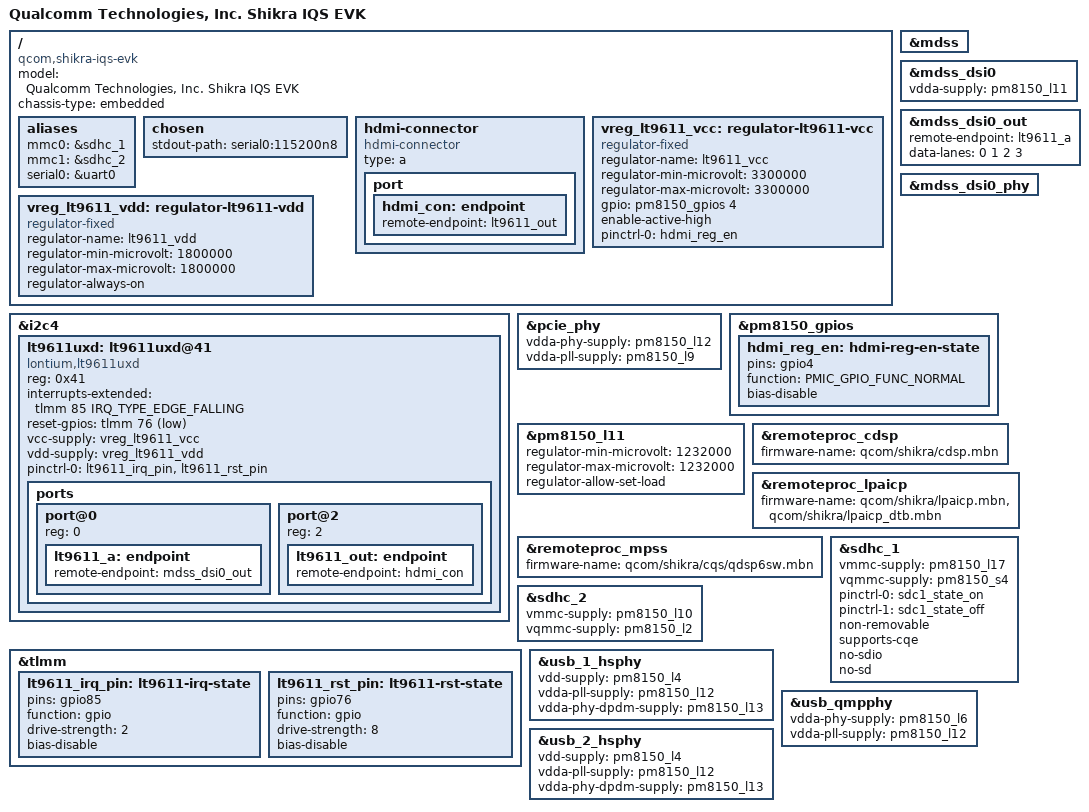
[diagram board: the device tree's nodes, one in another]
// SPDX-License-Identifier: BSD-3-Clause
/*
 * Copyright (c) Qualcomm Technologies, Inc. and/or its subsidiaries.
 */

/dts-v1/;

#include "shikra-iqs-som.dtsi"
#include "shikra-evk.dtsi"
#include <dt-bindings/gpio/gpio.h>
#include <dt-bindings/interrupt-controller/irq.h>

/ {
	model = "Qualcomm Technologies, Inc. Shikra IQS EVK";
	compatible = "qcom,shikra-iqs-evk", "qcom,shikra-iqs-som", "qcom,shikra";
	chassis-type = "embedded";

	aliases {
		mmc0 = &sdhc_1;
		mmc1 = &sdhc_2; /* SDC2 SD card slot */
		serial0 = &uart0;
	};

	chosen {
		stdout-path = "serial0:115200n8";
	};

	hdmi-connector {
		compatible = "hdmi-connector";
		type = "a";

		port {
			hdmi_con: endpoint {
				remote-endpoint = <&lt9611_out>;
			};
		};
	};

	vreg_lt9611_vcc: regulator-lt9611-vcc {
		compatible = "regulator-fixed";
		regulator-name = "lt9611_vcc";
		regulator-min-microvolt = <3300000>;
		regulator-max-microvolt = <3300000>;
		gpio = <&pm8150_gpios 4 GPIO_ACTIVE_HIGH>;
		enable-active-high;
		pinctrl-0 = <&hdmi_reg_en>;
		pinctrl-names = "default";
	};

	vreg_lt9611_vdd: regulator-lt9611-vdd {
		compatible = "regulator-fixed";
		regulator-name = "lt9611_vdd";
		regulator-min-microvolt = <1800000>;
		regulator-max-microvolt = <1800000>;
		regulator-always-on;
	};
};

&i2c4 {
	status = "okay";

	lt9611uxd: lt9611uxd@41 {
		compatible = "lontium,lt9611uxd";
		reg = <0x41>;
		interrupts-extended = <&tlmm 85 IRQ_TYPE_EDGE_FALLING>;
		reset-gpios = <&tlmm 76 GPIO_ACTIVE_LOW>;
		vcc-supply = <&vreg_lt9611_vcc>;
		vdd-supply = <&vreg_lt9611_vdd>;

		pinctrl-0 = <&lt9611_irq_pin &lt9611_rst_pin>;
		pinctrl-names = "default";

		ports {
			#address-cells = <1>;
			#size-cells = <0>;

			port@0 {
				reg = <0>;

				lt9611_a: endpoint {
					remote-endpoint = <&mdss_dsi0_out>;
				};
			};

			port@2 {
				reg = <2>;

				lt9611_out: endpoint {
					remote-endpoint = <&hdmi_con>;
				};
			};
		};
	};
};

&mdss {
	status = "okay";
};

&mdss_dsi0 {
	vdda-supply = <&pm8150_l11>;

	status = "okay";
};

&mdss_dsi0_out {
	remote-endpoint = <&lt9611_a>;
	data-lanes = <0 1 2 3>;
};

&mdss_dsi0_phy {
	status = "okay";
};

&pcie_phy {
	vdda-phy-supply = <&pm8150_l12>;
	vdda-pll-supply = <&pm8150_l9>;

	status = "okay";
};

&pm8150_gpios {
	hdmi_reg_en: hdmi-reg-en-state {
		pins = "gpio4";
		function = PMIC_GPIO_FUNC_NORMAL;
		bias-disable;
	};
};

&pm8150_l11 {
	regulator-min-microvolt = <1232000>;
	regulator-max-microvolt = <1232000>;
	regulator-allow-set-load;
};

&remoteproc_cdsp {
	firmware-name = "qcom/shikra/cdsp.mbn";

	status = "okay";
};

&remoteproc_lpaicp {
	firmware-name = "qcom/shikra/lpaicp.mbn",
			"qcom/shikra/lpaicp_dtb.mbn";

	status = "okay";
};

&remoteproc_mpss {
	firmware-name = "qcom/shikra/cqs/qdsp6sw.mbn";

	status = "okay";
};

&sdhc_1 {
	vmmc-supply = <&pm8150_l17>;
	vqmmc-supply = <&pm8150_s4>;

	pinctrl-0 = <&sdc1_state_on>;
	pinctrl-1 = <&sdc1_state_off>;
	pinctrl-names = "default", "sleep";

	non-removable;
	supports-cqe;
	no-sdio;
	no-sd;

	status = "okay";
};

&sdhc_2 {
	vmmc-supply = <&pm8150_l10>;
	vqmmc-supply = <&pm8150_l2>;

	status = "okay";
};

&tlmm {
	lt9611_irq_pin: lt9611-irq-state {
		pins = "gpio85";
		function = "gpio";
		drive-strength = <2>;
		bias-disable;
	};

	lt9611_rst_pin: lt9611-rst-state {
		pins = "gpio76";
		function = "gpio";
		drive-strength = <8>;
		bias-disable;
	};
};

&usb_1_hsphy {
	vdd-supply = <&pm8150_l4>;
	vdda-pll-supply = <&pm8150_l12>;
	vdda-phy-dpdm-supply = <&pm8150_l13>;

	status = "okay";
};

&usb_qmpphy {
	vdda-phy-supply = <&pm8150_l6>;
	vdda-pll-supply = <&pm8150_l12>;

	status = "okay";
};

&usb_2_hsphy {
	vdd-supply = <&pm8150_l4>;
	vdda-pll-supply = <&pm8150_l12>;
	vdda-phy-dpdm-supply = <&pm8150_l13>;

	status = "okay";
};
